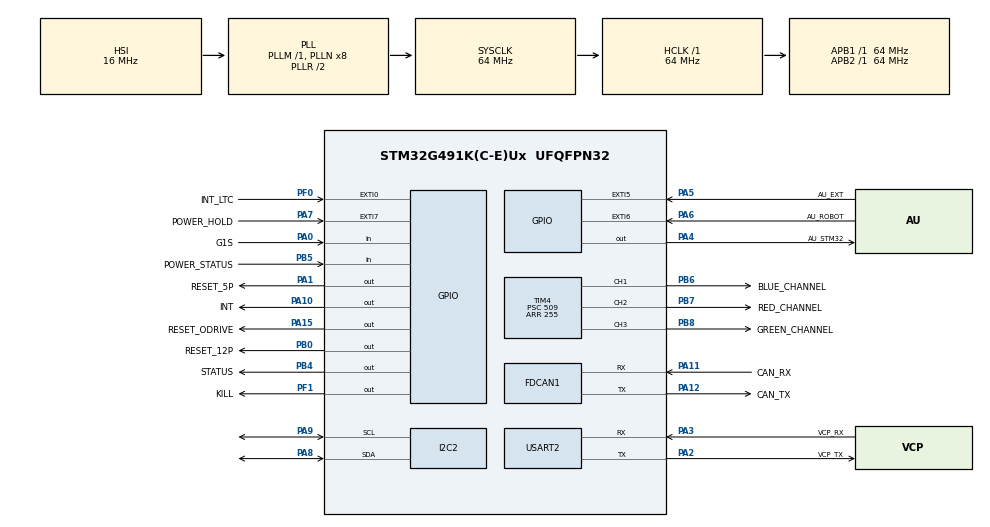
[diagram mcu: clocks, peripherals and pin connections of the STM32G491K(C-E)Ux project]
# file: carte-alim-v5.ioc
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FDCAN1.CalculateBaudRateNominal=1333333
FDCAN1.CalculateTimeBitNominal=750
FDCAN1.CalculateTimeQuantumNominal=250.0
I2C2.Timing=0x10B17DB5
Mcu.Family=STM32G4
Mcu.Name=STM32G491K(C-E)Ux
Mcu.Package=UFQFPN32
NVIC.EXTI0_IRQn=true\:0\:0\:false\:false\:true\:true\:true\:true
NVIC.PriorityGroup=NVIC_PRIORITYGROUP_4
PA0.GPIO_Label=G1S
PA0.GPIO_PuPd=GPIO_PULLUP
PA0.Signal=GPIO_Input
PA1.GPIO_Label=RESET_5P
PA1.GPIO_ModeDefaultOutputPP=GPIO_MODE_OUTPUT_OD
PA1.GPIO_PuPd=GPIO_NOPULL
PA1.PinState=GPIO_PIN_SET
PA1.Signal=GPIO_Output
PA10.GPIO_Label=INT
PA10.PinState=GPIO_PIN_SET
PA10.Signal=GPIO_Output
PA11.GPIO_Label=CAN_RX
PA11.Mode=FDCAN_Activate
PA11.Signal=FDCAN1_RX
PA12.GPIO_Label=CAN_TX
PA12.Mode=FDCAN_Activate
PA12.Signal=FDCAN1_TX
PA13.GPIO_Label=SWDIO
PA13.Mode=Trace_Asynchronous_SW
PA13.Signal=SYS_JTMS-SWDIO
PA14.GPIO_Label=SWCLK
PA14.Mode=Trace_Asynchronous_SW
PA14.Signal=SYS_JTCK-SWCLK
PA15.GPIO_Label=RESET_ODRIVE
PA15.PinState=GPIO_PIN_SET
PA15.Signal=GPIO_Output
PA2.GPIO_Label=VCP_TX
PA2.Mode=Asynchronous
PA2.Signal=USART2_TX
PA3.GPIO_Label=VCP_RX
PA3.Mode=Asynchronous
PA3.Signal=USART2_RX
PA4.GPIO_Label=AU_STM32
PA4.PinState=GPIO_PIN_SET
PA4.Signal=GPIO_Output
PA5.GPIO_Label=AU_EXT
PA5.GPIO_ModeDefaultEXTI=GPIO_MODE_IT_RISING_FALLING
PA5.GPIO_PuPd=GPIO_PULLDOWN
PA5.Signal=GPXTI5
PA6.GPIO_Label=AU_ROBOT
PA6.GPIO_ModeDefaultEXTI=GPIO_MODE_IT_RISING_FALLING
PA6.GPIO_PuPd=GPIO_PULLDOWN
PA6.Signal=GPXTI6
PA7.GPIO_Label=POWER_HOLD
PA7.GPIO_ModeDefaultEXTI=GPIO_MODE_IT_RISING_FALLING
PA7.GPIO_PuPd=GPIO_PULLDOWN
PA7.Signal=GPXTI7
PA8.Mode=I2C
PA8.Signal=I2C2_SDA
PA9.Mode=I2C
PA9.Signal=I2C2_SCL
PB0.GPIO_Label=RESET_12P
PB0.GPIO_ModeDefaultOutputPP=GPIO_MODE_OUTPUT_OD
PB0.GPIO_PuPd=GPIO_NOPULL
PB0.PinState=GPIO_PIN_SET
PB0.Signal=GPIO_Output
PB3.GPIO_Label=SWO
PB3.Mode=Trace_Asynchronous_SW
PB3.Signal=SYS_JTDO-SWO
PB4.GPIO_Label=STATUS
PB4.Signal=GPIO_Output
PB5.GPIO_Label=POWER_STATUS
PB5.GPIO_PuPd=GPIO_PULLDOWN
PB5.Signal=GPIO_Input
PB6.GPIO_Label=BLUE_CHANNEL
PB6.Signal=S_TIM4_CH1
PB7.GPIO_Label=RED_CHANNEL
PB7.Signal=S_TIM4_CH2
PB8-BOOT0.GPIO_Label=GREEN_CHANNEL
PB8-BOOT0.Signal=S_TIM4_CH3
PF0-OSC_IN.GPIO_Label=INT_LTC
PF0-OSC_IN.GPIO_ModeDefaultEXTI=GPIO_MODE_IT_FALLING
PF0-OSC_IN.GPIO_PuPd=GPIO_PULLUP
PF0-OSC_IN.Signal=GPXTI0
PF1-OSC_OUT.GPIO_Label=KILL
PF1-OSC_OUT.PinState=GPIO_PIN_SET
PF1-OSC_OUT.Signal=GPIO_Output
ProjectManager.HeapSize=0x200
ProjectManager.StackSize=0x400
ProjectManager.TargetToolchain=STM32CubeIDE
RCC.ADC12Freq_Value=64000000
RCC.ADC345Freq_Value=64000000
RCC.AHBFreq_Value=64000000
RCC.APB1Freq_Value=64000000
RCC.APB1TimFreq_Value=64000000
RCC.APB2Freq_Value=64000000
RCC.APB2TimFreq_Value=64000000
RCC.CortexFreq_Value=64000000
RCC.EXTERNAL_CLOCK_VALUE=12288000
RCC.HCLKFreq_Value=64000000
RCC.HSE_VALUE=8000000
RCC.HSI48_VALUE=48000000
RCC.HSI_VALUE=16000000
RCC.LSE_VALUE=32768
RCC.SYSCLKFreq_VALUE=64000000
RCC.SYSCLKSource=RCC_SYSCLKSOURCE_PLLCLK
RCC.USBFreq_Value=48000000
RCC.VCOOutputFreq_Value=128000000
SH.S_TIM4_CH1.0=TIM4_CH1,PWM Generation1 CH1
SH.S_TIM4_CH2.0=TIM4_CH2,PWM Generation2 CH2
SH.S_TIM4_CH3.0=TIM4_CH3,PWM Generation3 CH3
TIM4.Channel-PWM\ Generation1\ CH1=TIM_CHANNEL_1
TIM4.Channel-PWM\ Generation2\ CH2=TIM_CHANNEL_2
TIM4.Channel-PWM\ Generation3\ CH3=TIM_CHANNEL_3
TIM4.PeriodNoDither=255
TIM4.Prescaler=509
USART2.VirtualMode-Asynchronous=VM_ASYNC
VP_SYS_VS_DBSignals.Mode=DisableDeadBatterySignals
board=custom

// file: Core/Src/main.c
/* USER CODE BEGIN Header */
/**
  ******************************************************************************
  * @file           : main.c
  * @brief          : Main program body
  ******************************************************************************
  * @attention
  *
  * Copyright (c) 2025 STMicroelectronics.
  * All rights reserved.
  *
  * This software is licensed under terms that can be found in the LICENSE file
  * in the root directory of this software component.
  * If no LICENSE file comes with this software, it is provided AS-IS.
  *
  ******************************************************************************
  */
/* USER CODE END Header */
#include "main.h"

/* USER CODE BEGIN Includes */
#include <stdbool.h>
/* USER CODE END Includes */

FDCAN_HandleTypeDef hfdcan1;

I2C_HandleTypeDef hi2c2;

TIM_HandleTypeDef htim4;

UART_HandleTypeDef huart2;

/* USER CODE BEGIN PV */
typedef struct {
	uint8_t red;
	uint8_t green;
	uint8_t blue;
} color_t;

color_t Red = {100, 0 , 0};
color_t Orange = {80, 100, 0};
color_t Blue = {0, 0, 100};
color_t Green = {0, 255, 0};
color_t Purple = {20, 0, 80};
color_t White = {100, 100, 100};
color_t Black = {0, 0, 0};

bool RGB_State = false;

bool Compare_RGB_Color(color_t color1, color_t color2)
{
	return (
		color1.red == color2.red &&
		color1.green == color2.green &&
		color1.blue == color2.blue
	);
}

void Set_RGB_Button(color_t color)
{
	__HAL_TIM_SET_COMPARE(&htim4, TIM_CHANNEL_1, color.blue);
	__HAL_TIM_SET_COMPARE(&htim4, TIM_CHANNEL_2, color.red);
	__HAL_TIM_SET_COMPARE(&htim4, TIM_CHANNEL_3, color.green);

	RGB_State = !Compare_RGB_Color(color, Black);
}

void Blink_RGB_Button(color_t color)
{
	if (!RGB_State)
	{
		Set_RGB_Button(Red);
	}
	else
	{
		Set_RGB_Button(Black);
	}
}

void Init_RGB_Button()
{
	HAL_TIM_PWM_Start(&htim4, TIM_CHANNEL_1);
	HAL_TIM_PWM_Start(&htim4, TIM_CHANNEL_2);
	HAL_TIM_PWM_Start(&htim4, TIM_CHANNEL_3);

	Set_RGB_Button(Orange);
}

#define STATUS_BLINK_PERIOD	500
#define PH_BLINK_PERIOD	100
#define PH_WAINTING_TIME 15000
#define INT_PULSE_TIME 100

uint32_t Status_Last_Blink_Timestamp = 0;
uint32_t Interrupt_Start_Timestamp = 0;
/* USER CODE END PV */

void SystemClock_Config(void);
static void MX_GPIO_Init(void);
static void MX_USART2_UART_Init(void);
static void MX_I2C2_Init(void);
static void MX_FDCAN1_Init(void);
static void MX_TIM4_Init(void);

/* USER CODE BEGIN 0 */
void HAL_GPIO_EXTI_Callback(uint16_t GPIO_Pin)
{
	if (GPIO_Pin == INT_LTC_Pin)
	{
		HAL_GPIO_WritePin(INT_GPIO_Port, INT_Pin, GPIO_PIN_RESET);
		Set_RGB_Button(Purple);
		Interrupt_Start_Timestamp = HAL_GetTick();
	}
}
/* USER CODE END 0 */

int main(void)
{

  /* MCU Configuration--------------------------------------------------------*/

  /* Reset of all peripherals, Initializes the Flash interface and the Systick. */
  HAL_Init();

  /* Configure the system clock */
  SystemClock_Config();

  /* Initialize all configured peripherals */
  MX_GPIO_Init();
  MX_USART2_UART_Init();
  MX_I2C2_Init();
  MX_FDCAN1_Init();
  MX_TIM4_Init();
  /* USER CODE BEGIN 2 */
  Init_RGB_Button();
  /* USER CODE END 2 */

  /* Infinite loop */
  while (1)
  {

    /* USER CODE BEGIN 3 */
	uint32_t timestamp = HAL_GetTick();
	while (!HAL_GPIO_ReadPin(POWER_HOLD_GPIO_Port, POWER_HOLD_Pin))
	{
	  if (HAL_GetTick() - timestamp > PH_WAINTING_TIME)
	  {
	    HAL_GPIO_WritePin(KILL_GPIO_Port, KILL_Pin, GPIO_PIN_RESET);
	  }

	  Blink_RGB_Button(Red);
	   HAL_Delay(PH_BLINK_PERIOD);
    }

    if (timestamp - Interrupt_Start_Timestamp > INT_PULSE_TIME)
    {
      HAL_GPIO_WritePin(INT_GPIO_Port, INT_Pin, GPIO_PIN_SET);
      Interrupt_Start_Timestamp = timestamp;

      if (HAL_GPIO_ReadPin(G1S_GPIO_Port, G1S_Pin))
      {
        Set_RGB_Button(Green);
      }
      else
      {
        Set_RGB_Button(Blue);
      }
    }

    if (timestamp - Status_Last_Blink_Timestamp > STATUS_BLINK_PERIOD)
    {
      HAL_GPIO_TogglePin(STATUS_GPIO_Port, STATUS_Pin);
      Status_Last_Blink_Timestamp = timestamp;
    }
  }
  /* USER CODE END 3 */
}

void SystemClock_Config(void)
{
  RCC_OscInitTypeDef RCC_OscInitStruct = {0};
  RCC_ClkInitTypeDef RCC_ClkInitStruct = {0};

  /** Configure the main internal regulator output voltage
  */
  HAL_PWREx_ControlVoltageScaling(PWR_REGULATOR_VOLTAGE_SCALE1);

  /** Initializes the RCC Oscillators according to the specified parameters
  * in the RCC_OscInitTypeDef structure.
  */
  RCC_OscInitStruct.OscillatorType = RCC_OSCILLATORTYPE_HSI;
  RCC_OscInitStruct.HSIState = RCC_HSI_ON;
  RCC_OscInitStruct.HSICalibrationValue = RCC_HSICALIBRATION_DEFAULT;
  RCC_OscInitStruct.PLL.PLLState = RCC_PLL_ON;
  RCC_OscInitStruct.PLL.PLLSource = RCC_PLLSOURCE_HSI;
  RCC_OscInitStruct.PLL.PLLM = RCC_PLLM_DIV1;
  RCC_OscInitStruct.PLL.PLLN = 8;
  RCC_OscInitStruct.PLL.PLLP = RCC_PLLP_DIV2;
  RCC_OscInitStruct.PLL.PLLQ = RCC_PLLQ_DIV2;
  RCC_OscInitStruct.PLL.PLLR = RCC_PLLR_DIV2;
  if (HAL_RCC_OscConfig(&RCC_OscInitStruct) != HAL_OK)
  {
    Error_Handler();
  }

  /** Initializes the CPU, AHB and APB buses clocks
  */
  RCC_ClkInitStruct.ClockType = RCC_CLOCKTYPE_HCLK|RCC_CLOCKTYPE_SYSCLK
                              |RCC_CLOCKTYPE_PCLK1|RCC_CLOCKTYPE_PCLK2;
  RCC_ClkInitStruct.SYSCLKSource = RCC_SYSCLKSOURCE_PLLCLK;
  RCC_ClkInitStruct.AHBCLKDivider = RCC_SYSCLK_DIV1;
  RCC_ClkInitStruct.APB1CLKDivider = RCC_HCLK_DIV1;
  RCC_ClkInitStruct.APB2CLKDivider = RCC_HCLK_DIV1;

  if (HAL_RCC_ClockConfig(&RCC_ClkInitStruct, FLASH_LATENCY_2) != HAL_OK)
  {
    Error_Handler();
  }
}

static void MX_FDCAN1_Init(void)
{

  hfdcan1.Instance = FDCAN1;
  hfdcan1.Init.ClockDivider = FDCAN_CLOCK_DIV1;
  hfdcan1.Init.FrameFormat = FDCAN_FRAME_CLASSIC;
  hfdcan1.Init.Mode = FDCAN_MODE_NORMAL;
  hfdcan1.Init.AutoRetransmission = DISABLE;
  hfdcan1.Init.TransmitPause = DISABLE;
  hfdcan1.Init.ProtocolException = DISABLE;
  hfdcan1.Init.NominalPrescaler = 16;
  hfdcan1.Init.NominalSyncJumpWidth = 1;
  hfdcan1.Init.NominalTimeSeg1 = 1;
  hfdcan1.Init.NominalTimeSeg2 = 1;
  hfdcan1.Init.DataPrescaler = 1;
  hfdcan1.Init.DataSyncJumpWidth = 1;
  hfdcan1.Init.DataTimeSeg1 = 1;
  hfdcan1.Init.DataTimeSeg2 = 1;
  hfdcan1.Init.StdFiltersNbr = 0;
  hfdcan1.Init.ExtFiltersNbr = 0;
  hfdcan1.Init.TxFifoQueueMode = FDCAN_TX_FIFO_OPERATION;
  if (HAL_FDCAN_Init(&hfdcan1) != HAL_OK)
  {
    Error_Handler();
  }

}

static void MX_I2C2_Init(void)
{

  hi2c2.Instance = I2C2;
  hi2c2.Init.Timing = 0x10B17DB5;
  hi2c2.Init.OwnAddress1 = 0;
  hi2c2.Init.AddressingMode = I2C_ADDRESSINGMODE_7BIT;
  hi2c2.Init.DualAddressMode = I2C_DUALADDRESS_DISABLE;
  hi2c2.Init.OwnAddress2 = 0;
  hi2c2.Init.OwnAddress2Masks = I2C_OA2_NOMASK;
  hi2c2.Init.GeneralCallMode = I2C_GENERALCALL_DISABLE;
  hi2c2.Init.NoStretchMode = I2C_NOSTRETCH_DISABLE;
  if (HAL_I2C_Init(&hi2c2) != HAL_OK)
  {
    Error_Handler();
  }

  /** Configure Analogue filter
  */
  if (HAL_I2CEx_ConfigAnalogFilter(&hi2c2, I2C_ANALOGFILTER_ENABLE) != HAL_OK)
  {
    Error_Handler();
  }

  /** Configure Digital filter
  */
  if (HAL_I2CEx_ConfigDigitalFilter(&hi2c2, 0) != HAL_OK)
  {
    Error_Handler();
  }

}

static void MX_TIM4_Init(void)
{

  TIM_MasterConfigTypeDef sMasterConfig = {0};
  TIM_OC_InitTypeDef sConfigOC = {0};

  htim4.Instance = TIM4;
  htim4.Init.Prescaler = 509;
  htim4.Init.CounterMode = TIM_COUNTERMODE_UP;
  htim4.Init.Period = 255;
  htim4.Init.ClockDivision = TIM_CLOCKDIVISION_DIV1;
  htim4.Init.AutoReloadPreload = TIM_AUTORELOAD_PRELOAD_DISABLE;
  if (HAL_TIM_PWM_Init(&htim4) != HAL_OK)
  {
    Error_Handler();
  }
  sMasterConfig.MasterOutputTrigger = TIM_TRGO_RESET;
  sMasterConfig.MasterSlaveMode = TIM_MASTERSLAVEMODE_DISABLE;
  if (HAL_TIMEx_MasterConfigSynchronization(&htim4, &sMasterConfig) != HAL_OK)
  {
    Error_Handler();
  }
  sConfigOC.OCMode = TIM_OCMODE_PWM1;
  sConfigOC.Pulse = 0;
  sConfigOC.OCPolarity = TIM_OCPOLARITY_HIGH;
  sConfigOC.OCFastMode = TIM_OCFAST_DISABLE;
  if (HAL_TIM_PWM_ConfigChannel(&htim4, &sConfigOC, TIM_CHANNEL_1) != HAL_OK)
  {
    Error_Handler();
  }
  if (HAL_TIM_PWM_ConfigChannel(&htim4, &sConfigOC, TIM_CHANNEL_2) != HAL_OK)
  {
    Error_Handler();
  }
  if (HAL_TIM_PWM_ConfigChannel(&htim4, &sConfigOC, TIM_CHANNEL_3) != HAL_OK)
  {
    Error_Handler();
  }
  HAL_TIM_MspPostInit(&htim4);

}

static void MX_USART2_UART_Init(void)
{

  huart2.Instance = USART2;
  huart2.Init.BaudRate = 115200;
  huart2.Init.WordLength = UART_WORDLENGTH_8B;
  huart2.Init.StopBits = UART_STOPBITS_1;
  huart2.Init.Parity = UART_PARITY_NONE;
  huart2.Init.Mode = UART_MODE_TX_RX;
  huart2.Init.HwFlowCtl = UART_HWCONTROL_NONE;
  huart2.Init.OverSampling = UART_OVERSAMPLING_16;
  huart2.Init.OneBitSampling = UART_ONE_BIT_SAMPLE_DISABLE;
  huart2.Init.ClockPrescaler = UART_PRESCALER_DIV1;
  huart2.AdvancedInit.AdvFeatureInit = UART_ADVFEATURE_NO_INIT;
  if (HAL_UART_Init(&huart2) != HAL_OK)
  {
    Error_Handler();
  }
  if (HAL_UARTEx_SetTxFifoThreshold(&huart2, UART_TXFIFO_THRESHOLD_1_8) != HAL_OK)
  {
    Error_Handler();
  }
  if (HAL_UARTEx_SetRxFifoThreshold(&huart2, UART_RXFIFO_THRESHOLD_1_8) != HAL_OK)
  {
    Error_Handler();
  }
  if (HAL_UARTEx_DisableFifoMode(&huart2) != HAL_OK)
  {
    Error_Handler();
  }

}

static void MX_GPIO_Init(void)
{
  GPIO_InitTypeDef GPIO_InitStruct = {0};

  /* GPIO Ports Clock Enable */
  __HAL_RCC_GPIOF_CLK_ENABLE();
  __HAL_RCC_GPIOA_CLK_ENABLE();
  __HAL_RCC_GPIOB_CLK_ENABLE();

  /*Configure GPIO pin Output Level */
  HAL_GPIO_WritePin(KILL_GPIO_Port, KILL_Pin, GPIO_PIN_SET);

  /*Configure GPIO pin Output Level */
  HAL_GPIO_WritePin(GPIOA, RESET_5P_Pin|AU_STM32_Pin|INT_Pin|RESET_ODRIVE_Pin, GPIO_PIN_SET);

  /*Configure GPIO pin Output Level */
  HAL_GPIO_WritePin(RESET_12P_GPIO_Port, RESET_12P_Pin, GPIO_PIN_SET);

  /*Configure GPIO pin Output Level */
  HAL_GPIO_WritePin(STATUS_GPIO_Port, STATUS_Pin, GPIO_PIN_RESET);

  /*Configure GPIO pin : INT_LTC_Pin */
  GPIO_InitStruct.Pin = INT_LTC_Pin;
  GPIO_InitStruct.Mode = GPIO_MODE_IT_FALLING;
  GPIO_InitStruct.Pull = GPIO_PULLUP;
  HAL_GPIO_Init(INT_LTC_GPIO_Port, &GPIO_InitStruct);

  /*Configure GPIO pin : KILL_Pin */
  GPIO_InitStruct.Pin = KILL_Pin;
  GPIO_InitStruct.Mode = GPIO_MODE_OUTPUT_PP;
  GPIO_InitStruct.Pull = GPIO_NOPULL;
  GPIO_InitStruct.Speed = GPIO_SPEED_FREQ_LOW;
  HAL_GPIO_Init(KILL_GPIO_Port, &GPIO_InitStruct);

  /*Configure GPIO pin : G1S_Pin */
  GPIO_InitStruct.Pin = G1S_Pin;
  GPIO_InitStruct.Mode = GPIO_MODE_INPUT;
  GPIO_InitStruct.Pull = GPIO_PULLUP;
  HAL_GPIO_Init(G1S_GPIO_Port, &GPIO_InitStruct);

  /*Configure GPIO pin : RESET_5P_Pin */
  GPIO_InitStruct.Pin = RESET_5P_Pin;
  GPIO_InitStruct.Mode = GPIO_MODE_OUTPUT_OD;
  GPIO_InitStruct.Pull = GPIO_NOPULL;
  GPIO_InitStruct.Speed = GPIO_SPEED_FREQ_LOW;
  HAL_GPIO_Init(RESET_5P_GPIO_Port, &GPIO_InitStruct);

  /*Configure GPIO pins : AU_STM32_Pin INT_Pin RESET_ODRIVE_Pin */
  GPIO_InitStruct.Pin = AU_STM32_Pin|INT_Pin|RESET_ODRIVE_Pin;
  GPIO_InitStruct.Mode = GPIO_MODE_OUTPUT_PP;
  GPIO_InitStruct.Pull = GPIO_NOPULL;
  GPIO_InitStruct.Speed = GPIO_SPEED_FREQ_LOW;
  HAL_GPIO_Init(GPIOA, &GPIO_InitStruct);

  /*Configure GPIO pins : AU_EXT_Pin AU_ROBOT_Pin POWER_HOLD_Pin */
  GPIO_InitStruct.Pin = AU_EXT_Pin|AU_ROBOT_Pin|POWER_HOLD_Pin;
  GPIO_InitStruct.Mode = GPIO_MODE_IT_RISING_FALLING;
  GPIO_InitStruct.Pull = GPIO_PULLDOWN;
  HAL_GPIO_Init(GPIOA, &GPIO_InitStruct);

  /*Configure GPIO pin : RESET_12P_Pin */
  GPIO_InitStruct.Pin = RESET_12P_Pin;
  GPIO_InitStruct.Mode = GPIO_MODE_OUTPUT_OD;
  GPIO_InitStruct.Pull = GPIO_NOPULL;
  GPIO_InitStruct.Speed = GPIO_SPEED_FREQ_LOW;
  HAL_GPIO_Init(RESET_12P_GPIO_Port, &GPIO_InitStruct);

  /*Configure GPIO pin : STATUS_Pin */
  GPIO_InitStruct.Pin = STATUS_Pin;
  GPIO_InitStruct.Mode = GPIO_MODE_OUTPUT_PP;
  GPIO_InitStruct.Pull = GPIO_NOPULL;
  GPIO_InitStruct.Speed = GPIO_SPEED_FREQ_LOW;
  HAL_GPIO_Init(STATUS_GPIO_Port, &GPIO_InitStruct);

  /*Configure GPIO pin : POWER_STATUS_Pin */
  GPIO_InitStruct.Pin = POWER_STATUS_Pin;
  GPIO_InitStruct.Mode = GPIO_MODE_INPUT;
  GPIO_InitStruct.Pull = GPIO_PULLDOWN;
  HAL_GPIO_Init(POWER_STATUS_GPIO_Port, &GPIO_InitStruct);

  /* EXTI interrupt init*/
  HAL_NVIC_SetPriority(EXTI0_IRQn, 0, 0);
  HAL_NVIC_EnableIRQ(EXTI0_IRQn);

}

void Error_Handler(void)
{
  __disable_irq();
  while (1)
  {
  }
}
